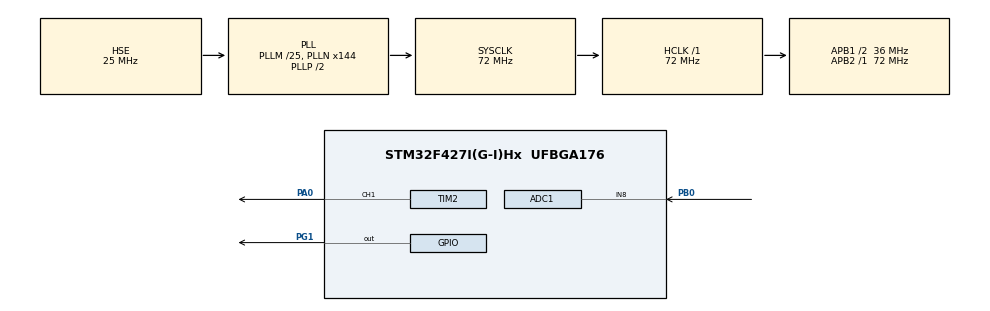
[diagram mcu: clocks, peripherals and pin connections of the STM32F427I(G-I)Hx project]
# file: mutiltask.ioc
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ADC1.Channel-0\#ChannelRegularConversion=ADC_CHANNEL_8
ADC1.ContinuousConvMode=ENABLE
ADC1.NbrOfConversionFlag=1
ADC1.Rank-0\#ChannelRegularConversion=1
ADC1.SamplingTime-0\#ChannelRegularConversion=ADC_SAMPLETIME_3CYCLES
ADC1.master=1
FREERTOS.INCLUDE_vTaskDelayUntil=1
FREERTOS.Tasks01=ledTask,0,128,led_Task,Default,NULL,Dynamic,NULL,NULL;detectTask,1,128,detect_Task,Default,NULL,Dynamic,NULL,NULL
Mcu.Family=STM32F4
Mcu.Name=STM32F427I(G-I)Hx
Mcu.Package=UFBGA176
NVIC.ADC_IRQn=true\:5\:0\:false\:false\:true\:true\:true\:true
NVIC.PriorityGroup=NVIC_PRIORITYGROUP_4
NVIC.TIM1_UP_TIM10_IRQn=true\:0\:0\:false\:false\:true\:false\:false\:true
NVIC.TimeBase=TIM1_UP_TIM10_IRQn
NVIC.TimeBaseIP=TIM1
PA0/WKUP.Signal=S_TIM2_CH1_ETR
PA13.Mode=Serial_Wire
PA13.Signal=SYS_JTMS-SWDIO
PA14.Mode=Serial_Wire
PA14.Signal=SYS_JTCK-SWCLK
PB0.Signal=ADCx_IN8
PG1.Signal=GPIO_Output
PH0/OSC_IN.Mode=HSE-External-Oscillator
PH0/OSC_IN.Signal=RCC_OSC_IN
PH1/OSC_OUT.Mode=HSE-External-Oscillator
PH1/OSC_OUT.Signal=RCC_OSC_OUT
ProjectManager.HeapSize=0x200
ProjectManager.StackSize=0x400
ProjectManager.TargetToolchain=MDK-ARM V5
RCC.48MHZClocksFreq_Value=36000000
RCC.AHBFreq_Value=72000000
RCC.APB1CLKDivider=RCC_HCLK_DIV2
RCC.APB1Freq_Value=36000000
RCC.APB1TimFreq_Value=72000000
RCC.APB2Freq_Value=72000000
RCC.APB2TimFreq_Value=72000000
RCC.CortexFreq_Value=72000000
RCC.HCLKFreq_Value=72000000
RCC.HSE_VALUE=25000000
RCC.HSI_VALUE=16000000
RCC.LSE_VALUE=32768
RCC.PLLM=25
RCC.PLLN=144
RCC.PLLSourceVirtual=RCC_PLLSOURCE_HSE
RCC.SYSCLKFreq_VALUE=72000000
RCC.SYSCLKSource=RCC_SYSCLKSOURCE_PLLCLK
RCC.VCOOutputFreq_Value=144000000
SH.ADCx_IN8.0=ADC1_IN8,IN8
SH.S_TIM2_CH1_ETR.0=TIM2_CH1,PWM Generation1 CH1
TIM2.AutoReloadPreload=TIM_AUTORELOAD_PRELOAD_ENABLE
TIM2.Channel-PWM\ Generation1\ CH1=TIM_CHANNEL_1
TIM2.Period=3599
TIM2.Prescaler=199
VP_FREERTOS_VS_CMSIS_V1.Mode=CMSIS_V1
VP_SYS_VS_tim1.Mode=TIM1
VP_TIM2_VS_ClockSourceINT.Mode=Internal
board=custom

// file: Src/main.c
/* USER CODE BEGIN Header */
/**
  ******************************************************************************
  * @file           : main.c
  * @brief          : Main program body
  ******************************************************************************
  * @attention
  *
  * <h2><center>&copy; Copyright (c) 2022 STMicroelectronics.
  * All rights reserved.</center></h2>
  *
  * This software component is licensed by ST under Ultimate Liberty license
  * SLA0044, the "License"; You may not use this file except in compliance with
  * the License. You may obtain a copy of the License at:
  *                             www.st.com/SLA0044
  *
  ******************************************************************************
  */
/* USER CODE END Header */

#include "main.h"
#include "cmsis_os.h"
#include "adc.h"
#include "tim.h"
#include "gpio.h"

void SystemClock_Config(void);
void MX_FREERTOS_Init(void);

int main(void)
{

  /* MCU Configuration--------------------------------------------------------*/

  /* Reset of all peripherals, Initializes the Flash interface and the Systick. */
  HAL_Init();

  /* Configure the system clock */
  SystemClock_Config();

  /* Initialize all configured peripherals */
  MX_GPIO_Init();
  MX_ADC1_Init();
  MX_TIM2_Init();

  /* Call init function for freertos objects (in freertos.c) */
  MX_FREERTOS_Init();

  /* Start scheduler */
  osKernelStart();

  /* We should never get here as control is now taken by the scheduler */

  /* Infinite loop */
  while (1)
  {

  }
}

void SystemClock_Config(void)
{
  RCC_OscInitTypeDef RCC_OscInitStruct = {0};
  RCC_ClkInitTypeDef RCC_ClkInitStruct = {0};

  /** Configure the main internal regulator output voltage
  */
  __HAL_RCC_PWR_CLK_ENABLE();
  __HAL_PWR_VOLTAGESCALING_CONFIG(PWR_REGULATOR_VOLTAGE_SCALE3);
  /** Initializes the CPU, AHB and APB busses clocks
  */
  RCC_OscInitStruct.OscillatorType = RCC_OSCILLATORTYPE_HSE;
  RCC_OscInitStruct.HSEState = RCC_HSE_ON;
  RCC_OscInitStruct.PLL.PLLState = RCC_PLL_ON;
  RCC_OscInitStruct.PLL.PLLSource = RCC_PLLSOURCE_HSE;
  RCC_OscInitStruct.PLL.PLLM = 25;
  RCC_OscInitStruct.PLL.PLLN = 144;
  RCC_OscInitStruct.PLL.PLLP = RCC_PLLP_DIV2;
  RCC_OscInitStruct.PLL.PLLQ = 4;
  if (HAL_RCC_OscConfig(&RCC_OscInitStruct) != HAL_OK)
  {
    Error_Handler();
  }
  /** Initializes the CPU, AHB and APB busses clocks
  */
  RCC_ClkInitStruct.ClockType = RCC_CLOCKTYPE_HCLK|RCC_CLOCKTYPE_SYSCLK
                              |RCC_CLOCKTYPE_PCLK1|RCC_CLOCKTYPE_PCLK2;
  RCC_ClkInitStruct.SYSCLKSource = RCC_SYSCLKSOURCE_PLLCLK;
  RCC_ClkInitStruct.AHBCLKDivider = RCC_SYSCLK_DIV1;
  RCC_ClkInitStruct.APB1CLKDivider = RCC_HCLK_DIV2;
  RCC_ClkInitStruct.APB2CLKDivider = RCC_HCLK_DIV1;

  if (HAL_RCC_ClockConfig(&RCC_ClkInitStruct, FLASH_LATENCY_2) != HAL_OK)
  {
    Error_Handler();
  }
}

void HAL_TIM_PeriodElapsedCallback(TIM_HandleTypeDef *htim)
{
  if (htim->Instance == TIM1) {
    HAL_IncTick();
  }
}

void Error_Handler(void)
{
}

/************************ (C) COPYRIGHT STMicroelectronics *****END OF FILE****/

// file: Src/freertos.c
/* USER CODE BEGIN Header */
/**
  ******************************************************************************
  * File Name          : freertos.c
  * Description        : Code for freertos applications
  ******************************************************************************
  * @attention
  *
  * <h2><center>&copy; Copyright (c) 2022 STMicroelectronics.
  * All rights reserved.</center></h2>
  *
  * This software component is licensed by ST under Ultimate Liberty license
  * SLA0044, the "License"; You may not use this file except in compliance with
  * the License. You may obtain a copy of the License at:
  *                             www.st.com/SLA0044
  *
  ******************************************************************************
  */
/* USER CODE END Header */

#include "FreeRTOS.h"
#include "task.h"
#include "main.h"
#include "cmsis_os.h"

/* USER CODE BEGIN Includes */
#include "gpio.h"
#include "adc.h"
#include "tim.h"
/* USER CODE END Includes */

/* USER CODE BEGIN Variables */
uint16_t ADC_value;
/* USER CODE END Variables */
osThreadId ledTaskHandle;
osThreadId detectTaskHandle;

/* USER CODE BEGIN FunctionPrototypes */
int ADC_get()
{

	HAL_ADC_Start(&hadc1);	//启动ADC转换
	HAL_ADC_PollForConversion(&hadc1, 50);	//等待转换完成，50ms为最大等待时间
	if(HAL_IS_BIT_SET(HAL_ADC_GetState(&hadc1), HAL_ADC_STATE_REG_EOC))
	{
		ADC_value = HAL_ADC_GetValue(&hadc1);		//获取AD值
	}
	return ADC_value;
}

void servo1(double angle)
{
		//大疆板子对应APB1外设，时钟频率对应36Mhz
		//三线舵机占空比为2.5%到12.5%，最小值为3599*2.5%=89.975 最大值为3599*12.5%=449.875
		//对应角度 ccr = 0.5*angle + 179
		double arr ;
		arr = angle + 90;
		TIM2->CCR1 = arr;

}
/* USER CODE END FunctionPrototypes */

void led_Task(void const * argument);
void detect_Task(void const * argument);

void MX_FREERTOS_Init(void); /* (MISRA C 2004 rule 8.1) */

/* GetIdleTaskMemory prototype (linked to static allocation support) */
void vApplicationGetIdleTaskMemory( StaticTask_t **ppxIdleTaskTCBBuffer, StackType_t **ppxIdleTaskStackBuffer, uint32_t *pulIdleTaskStackSize );

/* USER CODE BEGIN GET_IDLE_TASK_MEMORY */
static StaticTask_t xIdleTaskTCBBuffer;
static StackType_t xIdleStack[configMINIMAL_STACK_SIZE];

void vApplicationGetIdleTaskMemory( StaticTask_t **ppxIdleTaskTCBBuffer, StackType_t **ppxIdleTaskStackBuffer, uint32_t *pulIdleTaskStackSize )
{
  *ppxIdleTaskTCBBuffer = &xIdleTaskTCBBuffer;
  *ppxIdleTaskStackBuffer = &xIdleStack[0];
  *pulIdleTaskStackSize = configMINIMAL_STACK_SIZE;
  /* place for user code */
}
/* USER CODE END GET_IDLE_TASK_MEMORY */

void MX_FREERTOS_Init(void) {

  /* Create the thread(s) */
  /* definition and creation of ledTask */
  osThreadDef(ledTask, led_Task, osPriorityNormal, 0, 128);
  ledTaskHandle = osThreadCreate(osThread(ledTask), NULL);

  /* definition and creation of detectTask */
  osThreadDef(detectTask, detect_Task, osPriorityAboveNormal, 0, 128);
  detectTaskHandle = osThreadCreate(osThread(detectTask), NULL);

}

void led_Task(void const * argument)
{

  /* USER CODE BEGIN led_Task */
	TickType_t WakeTime = xTaskGetTickCount();
  /* Infinite loop */
  for(;;)
  {
		HAL_GPIO_WritePin(GPIOG, GPIO_PIN_1, 1);
    vTaskDelayUntil(&WakeTime, 1000);
		HAL_GPIO_WritePin(GPIOG, GPIO_PIN_1, 0);
		vTaskDelayUntil(&WakeTime, 1000);				//绝对延时
  }
  /* USER CODE END led_Task */
}

void detect_Task(void const * argument)
{
  /* USER CODE BEGIN detect_Task */

	HAL_TIM_PWM_Start(&htim2, TIM_CHANNEL_1);
  /* Infinite loop */
  for(;;)
  {
		//if(ADC_get() < 2520)
		//{
			//vTaskResume(detectTaskHandle);
			servo1(0);
			osDelay(1000);	//使该任务进入阻塞态，切换到另一任务（相对延时）

			servo1(100);

			osDelay(1000);
		//}
		//else
			//vTaskSuspend(detectTaskHandle);
    osDelay(1);
  }
  /* USER CODE END detect_Task */
}

/************************ (C) COPYRIGHT STMicroelectronics *****END OF FILE****/
